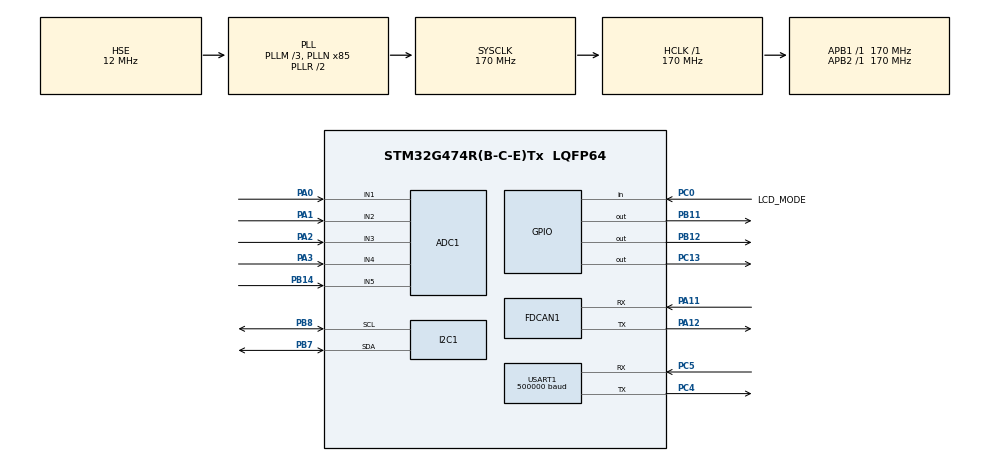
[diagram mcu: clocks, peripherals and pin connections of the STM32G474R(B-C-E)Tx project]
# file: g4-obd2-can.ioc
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ADC1.Channel-0\#ChannelRegularConversion=ADC_CHANNEL_1
ADC1.Channel-1\#ChannelRegularConversion=ADC_CHANNEL_2
ADC1.Channel-2\#ChannelRegularConversion=ADC_CHANNEL_3
ADC1.Channel-3\#ChannelRegularConversion=ADC_CHANNEL_4
ADC1.Channel-4\#ChannelRegularConversion=ADC_CHANNEL_5
ADC1.ContinuousConvMode=ENABLE
ADC1.DMAContinuousRequests=ENABLE
ADC1.NbrOfConversion=5
ADC1.NbrOfConversionFlag=1
ADC1.OffsetNumber-0\#ChannelRegularConversion=ADC_OFFSET_NONE
ADC1.OffsetNumber-1\#ChannelRegularConversion=ADC_OFFSET_NONE
ADC1.OffsetNumber-2\#ChannelRegularConversion=ADC_OFFSET_NONE
ADC1.OffsetNumber-3\#ChannelRegularConversion=ADC_OFFSET_NONE
ADC1.OffsetNumber-4\#ChannelRegularConversion=ADC_OFFSET_NONE
ADC1.Rank-0\#ChannelRegularConversion=1
ADC1.Rank-1\#ChannelRegularConversion=2
ADC1.Rank-2\#ChannelRegularConversion=3
ADC1.Rank-3\#ChannelRegularConversion=4
ADC1.Rank-4\#ChannelRegularConversion=5
ADC1.SamplingTime-0\#ChannelRegularConversion=ADC_SAMPLETIME_2CYCLES_5
ADC1.SamplingTime-1\#ChannelRegularConversion=ADC_SAMPLETIME_2CYCLES_5
ADC1.SamplingTime-2\#ChannelRegularConversion=ADC_SAMPLETIME_2CYCLES_5
ADC1.SamplingTime-3\#ChannelRegularConversion=ADC_SAMPLETIME_2CYCLES_5
ADC1.SamplingTime-4\#ChannelRegularConversion=ADC_SAMPLETIME_2CYCLES_5
ADC1.master=1
Dma.ADC1.2.Direction=DMA_PERIPH_TO_MEMORY
Dma.ADC1.2.EventEnable=DISABLE
Dma.ADC1.2.Instance=DMA2_Channel1
Dma.ADC1.2.MemDataAlignment=DMA_MDATAALIGN_WORD
Dma.ADC1.2.MemInc=DMA_MINC_ENABLE
Dma.ADC1.2.Mode=DMA_CIRCULAR
Dma.ADC1.2.PeriphDataAlignment=DMA_PDATAALIGN_WORD
Dma.ADC1.2.PeriphInc=DMA_PINC_DISABLE
Dma.ADC1.2.Polarity=HAL_DMAMUX_REQ_GEN_RISING
Dma.ADC1.2.Priority=DMA_PRIORITY_LOW
Dma.ADC1.2.RequestNumber=1
Dma.ADC1.2.SignalID=NONE
Dma.ADC1.2.SyncEnable=DISABLE
Dma.ADC1.2.SyncPolarity=HAL_DMAMUX_SYNC_NO_EVENT
Dma.ADC1.2.SyncRequestNumber=1
Dma.ADC1.2.SyncSignalID=NONE
Dma.Request0=USART1_RX
Dma.Request1=USART1_TX
Dma.Request2=ADC1
Dma.USART1_RX.0.Direction=DMA_PERIPH_TO_MEMORY
Dma.USART1_RX.0.EventEnable=DISABLE
Dma.USART1_RX.0.Instance=DMA1_Channel1
Dma.USART1_RX.0.MemDataAlignment=DMA_MDATAALIGN_BYTE
Dma.USART1_RX.0.MemInc=DMA_MINC_ENABLE
Dma.USART1_RX.0.Mode=DMA_NORMAL
Dma.USART1_RX.0.PeriphDataAlignment=DMA_PDATAALIGN_BYTE
Dma.USART1_RX.0.PeriphInc=DMA_PINC_DISABLE
Dma.USART1_RX.0.Polarity=HAL_DMAMUX_REQ_GEN_RISING
Dma.USART1_RX.0.Priority=DMA_PRIORITY_VERY_HIGH
Dma.USART1_RX.0.RequestNumber=1
Dma.USART1_RX.0.SignalID=NONE
Dma.USART1_RX.0.SyncEnable=DISABLE
Dma.USART1_RX.0.SyncPolarity=HAL_DMAMUX_SYNC_NO_EVENT
Dma.USART1_RX.0.SyncRequestNumber=1
Dma.USART1_RX.0.SyncSignalID=NONE
Dma.USART1_TX.1.Direction=DMA_MEMORY_TO_PERIPH
Dma.USART1_TX.1.EventEnable=DISABLE
Dma.USART1_TX.1.Instance=DMA1_Channel2
Dma.USART1_TX.1.MemDataAlignment=DMA_MDATAALIGN_BYTE
Dma.USART1_TX.1.MemInc=DMA_MINC_ENABLE
Dma.USART1_TX.1.Mode=DMA_NORMAL
Dma.USART1_TX.1.PeriphDataAlignment=DMA_PDATAALIGN_BYTE
Dma.USART1_TX.1.PeriphInc=DMA_PINC_DISABLE
Dma.USART1_TX.1.Polarity=HAL_DMAMUX_REQ_GEN_RISING
Dma.USART1_TX.1.Priority=DMA_PRIORITY_VERY_HIGH
Dma.USART1_TX.1.RequestNumber=1
Dma.USART1_TX.1.SignalID=NONE
Dma.USART1_TX.1.SyncEnable=DISABLE
Dma.USART1_TX.1.SyncPolarity=HAL_DMAMUX_SYNC_NO_EVENT
Dma.USART1_TX.1.SyncRequestNumber=1
Dma.USART1_TX.1.SyncSignalID=NONE
FDCAN1.CalculateBaudRateNominal=500000
FDCAN1.CalculateTimeBitNominal=2000
FDCAN1.CalculateTimeQuantumNominal=117.6470588235294
FDCAN1.ClockDivider=FDCAN_CLOCK_DIV10
FDCAN1.NominalPrescaler=2
FDCAN1.NominalTimeSeg1=11
FDCAN1.NominalTimeSeg2=5
I2C1.Timing=0x40B285C2
Mcu.Family=STM32G4
Mcu.Name=STM32G474R(B-C-E)Tx
Mcu.Package=LQFP64
NVIC.DMA1_Channel1_IRQn=true\:1\:0\:true\:false\:true\:false\:true\:true
NVIC.DMA1_Channel2_IRQn=true\:1\:0\:true\:false\:true\:false\:true\:true
NVIC.DMA2_Channel1_IRQn=true\:0\:0\:false\:false\:true\:false\:true\:true
NVIC.FDCAN1_IT0_IRQn=true\:3\:0\:true\:false\:true\:true\:true\:true
NVIC.PriorityGroup=NVIC_PRIORITYGROUP_4
NVIC.TIM1_UP_TIM16_IRQn=true\:0\:0\:true\:false\:true\:true\:true\:true
NVIC.USART1_IRQn=true\:2\:0\:true\:false\:true\:true\:true\:true
PA0.Mode=IN1-Single-Ended
PA0.Signal=ADC1_IN1
PA1.Mode=IN2-Single-Ended
PA1.Signal=ADC1_IN2
PA11.Mode=FDCAN_Activate
PA11.Signal=FDCAN1_RX
PA12.Mode=FDCAN_Activate
PA12.Signal=FDCAN1_TX
PA13.Mode=Serial_Wire
PA13.Signal=SYS_JTMS-SWDIO
PA14.Mode=Serial_Wire
PA14.Signal=SYS_JTCK-SWCLK
PA2.Mode=IN3-Single-Ended
PA2.Signal=ADC1_IN3
PA3.Mode=IN4-Single-Ended
PA3.Signal=ADC1_IN4
PB11.GPIO_Speed=GPIO_SPEED_FREQ_VERY_HIGH
PB11.PinState=GPIO_PIN_RESET
PB11.Signal=GPIO_Output
PB12.GPIO_Speed=GPIO_SPEED_FREQ_VERY_HIGH
PB12.Signal=GPIO_Output
PB14.Mode=IN5-Single-Ended
PB14.Signal=ADC1_IN5
PB7.Mode=I2C
PB7.Signal=I2C1_SDA
PB8-BOOT0.Mode=I2C
PB8-BOOT0.Signal=I2C1_SCL
PC0.GPIO_Label=LCD_MODE
PC0.Signal=GPIO_Input
PC13.Signal=GPIO_Output
PC4.GPIO_Speed=GPIO_SPEED_FREQ_VERY_HIGH
PC4.Mode=Asynchronous
PC4.Signal=USART1_TX
PC5.GPIO_Speed=GPIO_SPEED_FREQ_VERY_HIGH
PC5.Mode=Asynchronous
PC5.Signal=USART1_RX
PF0-OSC_IN.Mode=HSE-External-Oscillator
PF0-OSC_IN.Signal=RCC_OSC_IN
PF1-OSC_OUT.Mode=HSE-External-Oscillator
PF1-OSC_OUT.Signal=RCC_OSC_OUT
ProjectManager.HeapSize=0x200
ProjectManager.StackSize=0x400
ProjectManager.TargetToolchain=STM32CubeIDE
RCC.ADC12Freq_Value=170000000
RCC.ADC345Freq_Value=170000000
RCC.AHBFreq_Value=170000000
RCC.APB1Freq_Value=170000000
RCC.APB1TimFreq_Value=170000000
RCC.APB2Freq_Value=170000000
RCC.APB2TimFreq_Value=170000000
RCC.CortexFreq_Value=170000000
RCC.EXTERNAL_CLOCK_VALUE=12288000
RCC.HCLKFreq_Value=170000000
RCC.HSE_VALUE=12000000
RCC.HSI48_VALUE=48000000
RCC.HSI_VALUE=16000000
RCC.LSE_VALUE=32768
RCC.PLLM=RCC_PLLM_DIV3
RCC.PLLN=85
RCC.PLLSourceVirtual=RCC_PLLSOURCE_HSE
RCC.SYSCLKFreq_VALUE=170000000
RCC.SYSCLKSource=RCC_SYSCLKSOURCE_PLLCLK
RCC.USBFreq_Value=170000000
RCC.VCOOutputFreq_Value=340000000
TIM1.AutoReloadPreload=TIM_AUTORELOAD_PRELOAD_ENABLE
TIM1.Channel-PWM\ Generation1\ No\ Output=TIM_CHANNEL_1
TIM1.PeriodNoDither=99
TIM1.Prescaler=169
USART1.BaudRate=500000
USART1.DMADisableonRxErrorParam=ADVFEATURE_DMA_ENABLEONRXERROR
USART1.OverrunDisableParam=ADVFEATURE_OVERRUN_ENABLE
USART1.Parity=PARITY_EVEN
USART1.SwapParam=ADVFEATURE_SWAP_ENABLE
USART1.VirtualMode-Asynchronous=VM_ASYNC
USART1.WordLength=WORDLENGTH_9B
VP_SYS_VS_DBSignals.Mode=DisableDeadBatterySignals
VP_TIM1_VS_no_output1.Mode=PWM Generation1 No Output
board=custom

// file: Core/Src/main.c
/* USER CODE BEGIN Header */
/**
  ******************************************************************************
  * @file           : main.c
  * @brief          : Main program body
  ******************************************************************************
  * @attention
  *
  * Copyright (c) 2025 STMicroelectronics.
  * All rights reserved.
  *
  * This software is licensed under terms that can be found in the LICENSE file
  * in the root directory of this software component.
  * If no LICENSE file comes with this software, it is provided AS-IS.
  *
  ******************************************************************************
  */
/* USER CODE END Header */
#include "main.h"
#include "adc.h"
#include "dma.h"
#include "fdcan.h"
#include "i2c.h"
#include "tim.h"
#include "usart.h"
#include "gpio.h"

/* USER CODE BEGIN Includes */
#include "appl_main.h"

/* USER CODE END Includes */

void SystemClock_Config(void);

int main(void)
{

  /* MCU Configuration--------------------------------------------------------*/

  /* Reset of all peripherals, Initializes the Flash interface and the Systick. */
  HAL_Init();

  /* Configure the system clock */
  SystemClock_Config();

  /* Initialize all configured peripherals */
  MX_GPIO_Init();
  MX_DMA_Init();
  MX_USART1_UART_Init();
  MX_TIM1_Init();
  MX_FDCAN1_Init();
  MX_I2C1_Init();
  MX_ADC1_Init();
  /* USER CODE BEGIN 2 */
  HAL_Delay(1000);
  custom_init();
  /* USER CODE END 2 */

  /* Infinite loop */
  /* USER CODE BEGIN WHILE */
  while (1)
  {
    main_loop();
    /* USER CODE END WHILE */

  }
}

void SystemClock_Config(void)
{
  RCC_OscInitTypeDef RCC_OscInitStruct = {0};
  RCC_ClkInitTypeDef RCC_ClkInitStruct = {0};

  /** Configure the main internal regulator output voltage
  */
  HAL_PWREx_ControlVoltageScaling(PWR_REGULATOR_VOLTAGE_SCALE1_BOOST);

  /** Initializes the RCC Oscillators according to the specified parameters
  * in the RCC_OscInitTypeDef structure.
  */
  RCC_OscInitStruct.OscillatorType = RCC_OSCILLATORTYPE_HSE;
  RCC_OscInitStruct.HSEState = RCC_HSE_ON;
  RCC_OscInitStruct.PLL.PLLState = RCC_PLL_ON;
  RCC_OscInitStruct.PLL.PLLSource = RCC_PLLSOURCE_HSE;
  RCC_OscInitStruct.PLL.PLLM = RCC_PLLM_DIV3;
  RCC_OscInitStruct.PLL.PLLN = 85;
  RCC_OscInitStruct.PLL.PLLP = RCC_PLLP_DIV2;
  RCC_OscInitStruct.PLL.PLLQ = RCC_PLLQ_DIV2;
  RCC_OscInitStruct.PLL.PLLR = RCC_PLLR_DIV2;
  if (HAL_RCC_OscConfig(&RCC_OscInitStruct) != HAL_OK)
  {
    Error_Handler();
  }

  /** Initializes the CPU, AHB and APB buses clocks
  */
  RCC_ClkInitStruct.ClockType = RCC_CLOCKTYPE_HCLK|RCC_CLOCKTYPE_SYSCLK
                              |RCC_CLOCKTYPE_PCLK1|RCC_CLOCKTYPE_PCLK2;
  RCC_ClkInitStruct.SYSCLKSource = RCC_SYSCLKSOURCE_PLLCLK;
  RCC_ClkInitStruct.AHBCLKDivider = RCC_SYSCLK_DIV1;
  RCC_ClkInitStruct.APB1CLKDivider = RCC_HCLK_DIV1;
  RCC_ClkInitStruct.APB2CLKDivider = RCC_HCLK_DIV1;

  if (HAL_RCC_ClockConfig(&RCC_ClkInitStruct, FLASH_LATENCY_4) != HAL_OK)
  {
    Error_Handler();
  }
}

void Error_Handler(void)
{
  __disable_irq();
  while (1)
  {
  }
}
